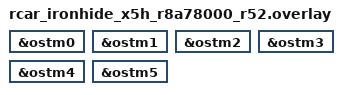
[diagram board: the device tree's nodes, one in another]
/*
 * Copyright (c) 2026 Renesas Electronics Corporation
 *
 * SPDX-License-Identifier: Apache-2.0
 */

&ostm0 {
	status = "okay";
};

&ostm1 {
	status = "okay";
};

&ostm2 {
	status = "okay";
};

&ostm3 {
	status = "okay";
};

&ostm4 {
	status = "okay";
};

&ostm5 {
	status = "okay";
};
